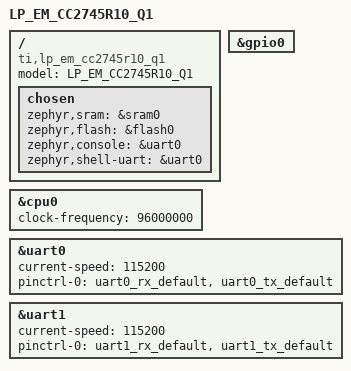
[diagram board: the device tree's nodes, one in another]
/*
 * Copyright (c) 2025 Texas Instruments Incorporated
 * Copyright (c) 2024 BayLibre, SAS
 *
 * SPDX-License-Identifier: Apache-2.0
 */

/dts-v1/;

#include <ti/cc2745r10_q1.dtsi>
#include "boosterpack_connector.dtsi"
#include "lp_em_cc2745r10_q1-pinctrl.dtsi"

/ {
	model = "LP_EM_CC2745R10_Q1";
	compatible = "ti,lp_em_cc2745r10_q1";

	chosen {
		zephyr,sram = &sram0;
		zephyr,flash = &flash0;
		zephyr,console = &uart0;
		zephyr,shell-uart = &uart0;
	};

};

&cpu0 {
	clock-frequency = <96000000>;
};

&gpio0 {
	status = "okay";
};

&uart0{
	status = "okay";
	current-speed = <115200>;
	pinctrl-0 = <&uart0_rx_default &uart0_tx_default>;
	pinctrl-names = "default";
};

&uart1{
	status = "okay";
	current-speed = <115200>;
	pinctrl-0 = <&uart1_rx_default &uart1_tx_default>;
	pinctrl-names = "default";
};
